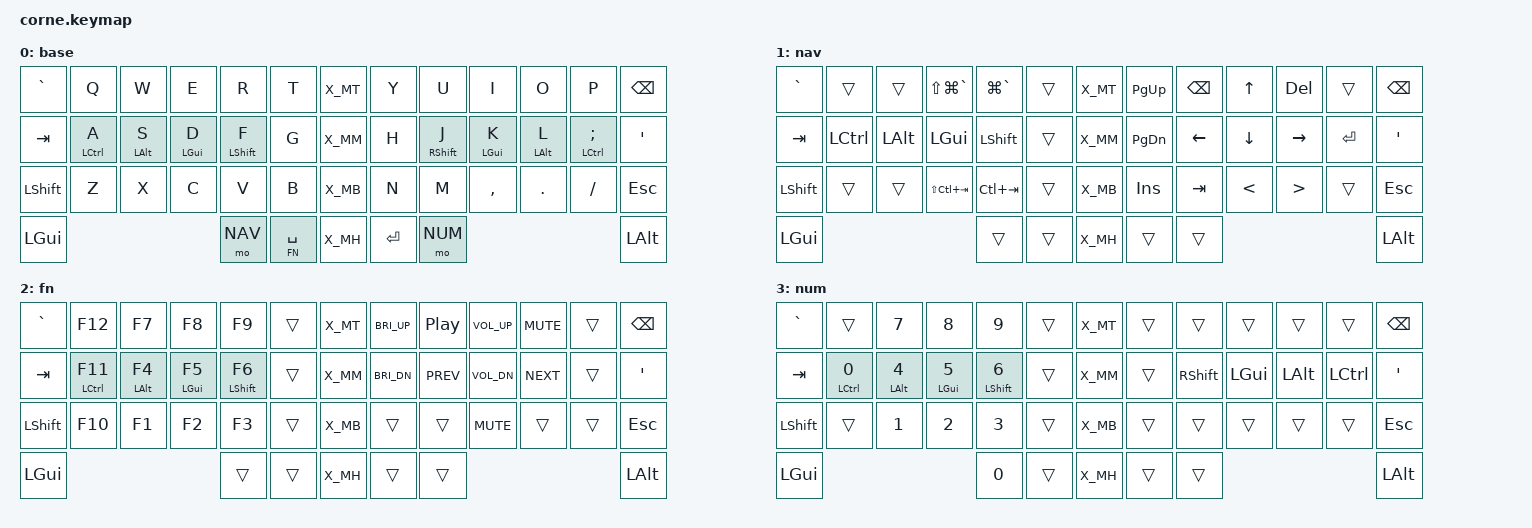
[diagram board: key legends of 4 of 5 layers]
/*
 * Copyright (c) 2020 The ZMK Contributors
 *
 * SPDX-License-Identifier: MIT
 */

/* Define key layout */
#include "zmk-helpers/key-labels/42.h"

/* Map extra keys */
#define X_LT &kp GRAVE  // Top
#define X_LM &kp TAB    // Middle
#define X_LB &kp LSHFT  // Bottom
#define X_LH &kp LGUI   // Thumb

#define X_RT &kp BSPC  // Top
#define X_RM &kp SQT   // Middle
#define X_RB &kp ESC   // Bottom
#define X_RH &kp LALT // Thumb

/* between left and right half */
#if !defined X_MT  // top row, middle
    #define X_MT
#endif
#if !defined X_MM  // middle row, middle
    #define X_MM
#endif
#if !defined X_MB  // bottom row, middle
    #define X_MB
#endif
#if !defined X_MH  // thumb row, middle
    #define X_MH
#endif


/* Map custom modded keys */
#define N_APP &kp LG(TAB)
#define P_APP &kp LS(LG(TAB))
#define N_WIN &kp LG(GRAVE)
#define P_WIN &kp LS(LG(GRAVE))
#define N_TAB &kp LC(TAB)
#define P_TAB &kp LS(LC(TAB))

/* Enable wireless */
#define CONFIG_WIRELESS


#include <behaviors.dtsi>
#include <dt-bindings/zmk/keys.h>
#ifdef CONFIG_WIRELESS
    #include <dt-bindings/zmk/bt.h>
    #define _BT_SEL_KEYS_ &bt BT_SEL 0 &bt BT_SEL 1 &bt BT_SEL 2 &bt BT_SEL 3 &bt BT_CLR
#else
    #define _BT_SEL_KEYS_ &trans &trans &trans &trans &trans
#endif

#include "zmk-helpers/helper.h"

// Layer References

#define DEF 0
#define NAV 1
#define FN 2
#define NUM 3
#define SYS 4
#define UC 5
#define MOUSE 6

#include "combos.dtsi"  // requires layer aliases

#define XXX &none
#define ___ &trans

/* Global settings */

#define QUICK_TAP_MS 175

&sk {  // sticky-key config
    release-after-ms = <900>;  // release after 0.6s
    quick-release;             // no double capitalization when rolling keys
};

&sl {  // sticky-layer config
    ignore-modifiers;          // allow chording sticky mods & layers
};

&lt {  // layer-tap config
    flavor = "balanced";
    tapping-term-ms = <200>;
    quick-tap-ms = <QUICK_TAP_MS>;
};

/* Homerow mods */

#define KEYS_L LT0 LT1 LT2 LT3 LT4 LT5 LM0 LM1 LM2 LM3 LM4 LM5 LB0 LB1 LB2 LB3 LB4 LB5 // left hand
#define KEYS_R RT0 RT1 RT2 RT3 RT4 RT5 RM0 RM1 RM2 RM3 RM4 RM5 RB0 RB1 RB2 RB3 RB4 RB5 // right hand
#define THUMBS LH2 LH1 LH0 RH0 RH1 RH2                                                 // thumbs

#define MAKE_HRM(NAME, HOLD, TAP, TRIGGER_POS) \
    ZMK_HOLD_TAP(NAME, \
        flavor = "balanced"; \
        tapping-term-ms = <280>; \
        quick-tap-ms = <QUICK_TAP_MS>; \
        require-prior-idle-ms = <150>; \
        bindings = <HOLD>, <TAP>; \
        hold-trigger-key-positions = <TRIGGER_POS>; \
        hold-trigger-on-release; \
    )
MAKE_HRM(hml, &kp, &kp, KEYS_R THUMBS)  // left-hand HRMs
MAKE_HRM(hmr, &kp, &kp, KEYS_L THUMBS)  // right-hand HRMs

MAKE_HRM(hml_repeat, &kp, &key_repeat, KEYS_R THUMBS)  // used for HRM-combo
MAKE_HRM(hmr_lpar_lt, &kp, &lpar_lt, KEYS_L THUMBS)    // "    "   "   "
MAKE_HRM(hmr_rpar_gt, &kp, &rpar_gt, KEYS_L THUMBS)    // "    "   "   "

/* Nav cluster */

// Note: these are left as references for ease of use if we ever want to use urob long-press nav stuff
#define NAV_LEFT  &kp LEFT
#define NAV_RIGHT &kp RIGHT
#define NAV_UP    &kp UP
#define NAV_DOWN  &kp DOWN
#define NAV_BSPC  &kp BSPC
#define NAV_DEL   &kp DEL

/* Simple mod morph definitions */

// reuse basic mod-morph scheme
#define SIMPLE_MORPH(NAME, MOD, BINDING1, BINDING2) \
    ZMK_MOD_MORPH(NAME, \
        mods = <(MOD_L ## MOD|MOD_R ## MOD)>; \
        bindings = <BINDING1>, <BINDING2>; \
    )

// tap: comma | shift + tap: semicolon | ctrl + shift + tap: <
// UNUSED
//SIMPLE_MORPH(comma_morph, SFT, &kp COMMA, &comma_inner_morph)
//SIMPLE_MORPH(comma_inner_morph, CTL, &kp SEMICOLON, &kp LESS_THAN)

// tap: dot | shift + tap: colon | ctrl + shift + tap: >
// UNUSED
//SIMPLE_MORPH(dot_morph, SFT, &kp DOT, &dot_inner_morph)
//SIMPLE_MORPH(dot_inner_morph, CTL, &kp COLON, &kp GREATER_THAN)

// tap: qmark | shift + tap: excl
// UNUSED
//SIMPLE_MORPH(qexcl, SFT, &kp QMARK, &kp EXCL)

// tap: left/right parenthesis | shft + tap: braces
SIMPLE_MORPH(lpar_lt, SFT, &kp LPAR, &kp LBRC)
SIMPLE_MORPH(rpar_gt, SFT, &kp RPAR, &kp RBRC)

// tap: space | hold: activate layer
ZMK_HOLD_TAP(lt_spc,
    flavor = "balanced";
    tapping-term-ms = <200>;
    quick-tap-ms = <QUICK_TAP_MS>;
    bindings = <&mo>, <&kp>;
)

ZMK_CONDITIONAL_LAYER(sys, FN NUM, SYS)  // FN + NUM --> SYS

ZMK_LAYER(base,
//╭──────╮ ╭─────────────┬─────────────┬─────────────┬─────────────┬─────────────╮ ╭──────╮ ╭─────────────┬─────────────┬─────────────┬─────────────┬───────────────╮ ╭──────╮
    X_LT     &kp Q         &kp W         &kp E         &kp R         &kp T           X_MT     &kp Y         &kp U         &kp I         &kp O         &kp P             X_RT
//├──────┤ ├─────────────┼─────────────┼─────────────┼─────────────┼─────────────┤ ├──────┤ ├─────────────┼─────────────┼─────────────┼─────────────┼───────────────┤ ├──────┤
    X_LM     &hml LCTRL A  &hml LALT S   &hml LGUI D   &hml LSHFT F  &kp G           X_MM     &kp H         &hmr RSHFT J  &hmr LGUI K   &hmr LALT L   &hmr LCTRL SEMI   X_RM
//├──────┤ ├─────────────┼─────────────┼─────────────┼─────────────┼─────────────┤ ├──────┤ ├─────────────┼─────────────┼─────────────┼─────────────┼───────────────┤ ├──────┤
    X_LB     &kp Z         &kp X         &kp C         &kp V         &kp B           X_MB     &kp N         &kp M         &kp COMMA     &kp DOT       &kp FSLH          X_RB
//├──────┤ ╰─────────────┼─────────────┴─────────────┼─────────────┼─────────────┤ ├──────┤ ├─────────────┼─────────────┼─────────────┴─────────────────────────────╯ ├──────┤
    X_LH                                               &mo NAV       &lt_spc FN SPACE X_MH    &kp RET       &mo NUM                                                     X_RH
//╰──────╯                                           ╰─────────────┴─────────────╯ ╰──────╯ ╰─────────────┴─────────────╯                                             ╰──────╯
)

ZMK_LAYER(nav,
//╭──────╮ ╭─────────────┬─────────────┬─────────────┬─────────────┬─────────────╮ ╭──────╮ ╭─────────────┬─────────────┬─────────────┬─────────────┬─────────────╮ ╭──────╮
    X_LT     ___           ___           P_WIN         N_WIN         ___             X_MT     &kp PG_UP     NAV_BSPC      NAV_UP        NAV_DEL       ___             X_RT
//├──────┤ ├─────────────┼─────────────┼─────────────┼─────────────┼─────────────┤ ├──────┤ ├─────────────┼─────────────┼─────────────┼─────────────┼─────────────┤ ├──────┤
    X_LM     &kp LCTRL     &kp LALT      &kp LGUI      &kp LSHFT     ___             X_MM     &kp PG_DN     NAV_LEFT      NAV_DOWN      NAV_RIGHT     &kp RET         X_RM
//├──────┤ ├─────────────┼─────────────┼─────────────┼─────────────┼─────────────┤ ├──────┤ ├─────────────┼─────────────┼─────────────┼─────────────┼─────────────┤ ├──────┤
    X_LB     ___           ___           P_TAB         N_TAB         ___             X_MB     &kp INS       &kp TAB       &kp LT        &kp GT        ___             X_RB
//├──────┤ ╰─────────────┼─────────────┴─────────────┼─────────────┼─────────────┤ ├──────┤ ├─────────────┼─────────────┼─────────────┴───────────────────────────╯ ├──────┤
    X_LH                                               ___           ___             X_MH     ___           ___                                                       X_RH
//╰──────╯                                           ╰─────────────┴─────────────╯ ╰──────╯ ╰─────────────┴─────────────╯                                           ╰──────╯
)

ZMK_LAYER(fn,
//╭──────╮ ╭─────────────┬─────────────┬─────────────┬─────────────┬─────────────╮ ╭──────╮ ╭─────────────┬─────────────┬─────────────┬─────────────┬─────────────╮ ╭──────╮
    X_LT     &kp F12       &kp F7        &kp F8        &kp F9        ___             X_MT     &kp C_BRI_UP  &kp C_PP      &kp C_VOL_UP  &kp C_MUTE    ___             X_RT
//├──────┤ ├─────────────┼─────────────┼─────────────┼─────────────┼─────────────┤ ├──────┤ ├─────────────┼─────────────┼─────────────┼─────────────┼─────────────┤ ├──────┤
    X_LM     &hml LCTRL F11 &hml LALT F4 &hml LGUI F5 &hml LSHFT F6  ___             X_MM     &kp C_BRI_DN  &kp C_PREV    &kp C_VOL_DN  &kp C_NEXT    ___             X_RM
//├──────┤ ├─────────────┼─────────────┼─────────────┼─────────────┼─────────────┤ ├──────┤ ├─────────────┼─────────────┼─────────────┼─────────────┼─────────────┤ ├──────┤
    X_LB     &kp F10       &kp F1        &kp F2        &kp F3        ___             X_MB     ___           ___           &kp C_MUTE    ___           ___             X_RB
//├──────┤ ╰─────────────┼─────────────┴─────────────┼─────────────┼─────────────┤ ├──────┤ ├─────────────┼─────────────┼─────────────┴───────────────────────────╯ ├──────┤
    X_LH                                               ___           ___             X_MH     ___           ___                                                       X_RH
//╰──────╯                                           ╰─────────────┴─────────────╯ ╰──────╯ ╰─────────────┴─────────────╯                                           ╰──────╯
)

ZMK_LAYER(num,
//╭──────╮ ╭─────────────┬─────────────┬─────────────┬─────────────┬─────────────╮ ╭──────╮ ╭─────────────┬─────────────┬─────────────┬─────────────┬─────────────╮ ╭──────╮
    X_LT     ___           &kp N7        &kp N8        &kp N9        ___             X_MT     ___           ___           ___           ___           ___             X_RT
//├──────┤ ├─────────────┼─────────────┼─────────────┼─────────────┼─────────────┤ ├──────┤ ├─────────────┼─────────────┼─────────────┼─────────────┼─────────────┤ ├──────┤
    X_LM     &hml LCTRL N0 &hml LALT N4  &hml LGUI N5  &hml LSHFT N6 ___             X_MM     ___           &kp RSHFT     &kp LGUI      &kp LALT      &kp LCTRL       X_RM
//├──────┤ ├─────────────┼─────────────┼─────────────┼─────────────┼─────────────┤ ├──────┤ ├─────────────┼─────────────┼─────────────┼─────────────┼─────────────┤ ├──────┤
    X_LB     ___           &kp N1        &kp N2        &kp N3        ___             X_MB     ___           ___           ___           ___           ___             X_RB
//├──────┤ ╰─────────────┼─────────────┴─────────────┼─────────────┼─────────────┤ ├──────┤ ├─────────────┼─────────────┼─────────────┴───────────────────────────╯ ├──────┤
    X_LH                                               &kp N0        ___             X_MH     ___           ___                                                       X_RH
//╰──────╯                                           ╰─────────────┴─────────────╯ ╰──────╯ ╰─────────────┴─────────────╯                                           ╰──────╯
)

ZMK_LAYER(sys,
//╭──────╮ ╭─────────────┬─────────────┬─────────────┬─────────────┬─────────────╮ ╭──────╮ ╭─────────────┬─────────────┬─────────────┬─────────────┬─────────────╮ ╭──────╮
    X_LT                                _BT_SEL_KEYS_                                X_MT     ___           ___           ___           ___           ___             X_RT
//├──────┤ ├─────────────┼─────────────┼─────────────┼─────────────┼─────────────┤ ├──────┤ ├─────────────┼─────────────┼─────────────┼─────────────┼─────────────┤ ├──────┤
    X_LM     ___           ___           ___           ___           &bootloader     X_MM     &bootloader   ___           ___           ___           ___             X_RM
//├──────┤ ├─────────────┼─────────────┼─────────────┼─────────────┼─────────────┤ ├──────┤ ├─────────────┼─────────────┼─────────────┼─────────────┼─────────────┤ ├──────┤
    X_LB     ___           ___           ___           ___           &sys_reset      X_MB     &sys_reset    ___           ___           ___           ___             X_RB
//├──────┤ ╰─────────────┼─────────────┴─────────────┼─────────────┼─────────────┤ ├──────┤ ├─────────────┼─────────────┼─────────────┴───────────────────────────╯ ├──────┤
    X_LH                                               ___           ___             X_MH     ___           ___                                                       X_RH
//╰──────╯                                           ╰─────────────┴─────────────╯ ╰──────╯ ╰─────────────┴─────────────╯                                           ╰──────╯
)
